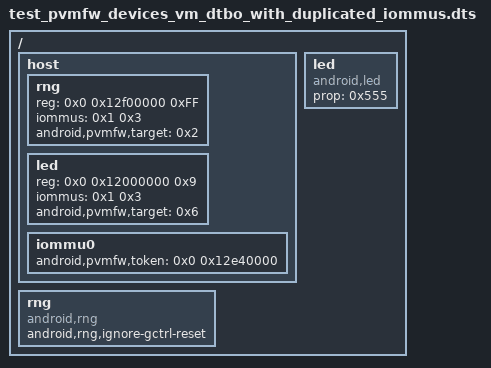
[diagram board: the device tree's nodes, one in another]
/dts-v1/;

/ {
    host {
        #address-cells = <0x2>;
        #size-cells = <0x1>;
        rng {
            reg = <0x0 0x12f00000 0xFF>;
            iommus = <0x1 0x3>;
            android,pvmfw,target = <0x2>;
        };
        led {
            reg = <0x0 0x12000000 0x9>;
            iommus = <0x1 0x3>;
            android,pvmfw,target = <0x6>;
        };
        iommu0 {
            #iommu-cells = <0x1>;
            android,pvmfw,token = <0x0 0x12e40000>;
            phandle = <0x1>;
        };
    };
    fragment@rng {
        target-path = "/";
        __overlay__ {
            rng {
                compatible = "android,rng";
                android,rng,ignore-gctrl-reset;
                phandle = <0x2>;
            };
        };
    };
    fragment@led {
        target-path = "/";
        __overlay__ {
            led {
                compatible = "android,led";
                prop = <0x555>;
                phandle = <0x6>;
            };
        };
    };
    __symbols__ {
        iommu0 = "/host/iommu0";
        rng = "/fragment@rng/__overlay__/rng";
        led = "/fragment@led/__overlay__/led";
    };
    __local_fixups__ {
        host {
            rng {
                iommus = <0x0>;
                android,pvmfw,target = <0x0>;
            };
            led {
                iommus = <0x0>;
                android,pvmfw,target = <0x0>;
            };
        };
    };
};
